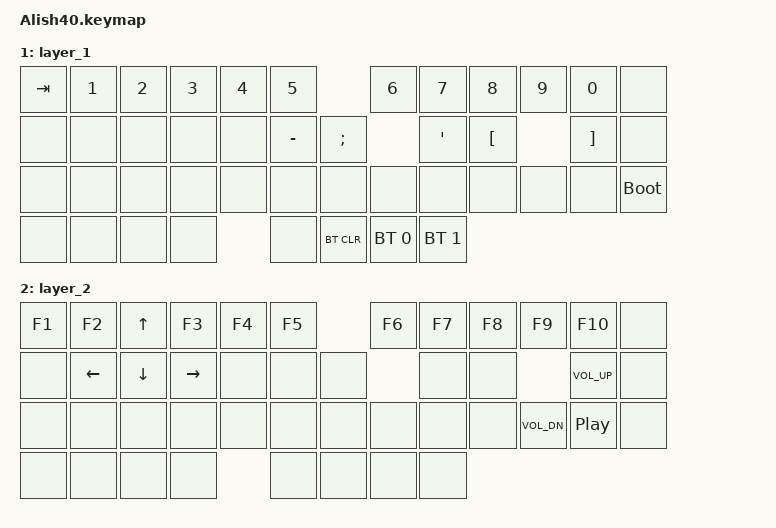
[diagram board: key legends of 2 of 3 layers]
#include <behaviors.dtsi>
#include <dt-bindings/zmk/keys.h>
#include <dt-bindings/zmk/bt.h>

/ {
    keymap {
        compatible = "zmk,keymap";

        default_layer {
            bindings = <
                &kp ESC   &kp Q   &kp W    &kp E   &kp R   &kp T   &kp Y   &kp U   &kp I   &kp O   &kp P   &kp BACKSPACE
                &kp CAPS   &kp A   &kp S    &kp D   &kp F   &kp G   &kp H   &kp J   &kp K   &kp L   &kp SQT   &kp RETURN
                &kp LSHIFT   &kp SLASH   &kp Z   &kp X   &kp C   &kp V   &kp B   &kp B   &kp N   &kp M   &kp COMMA   &kp PERIOD   &kp RSHFT
                &kp LCTRL   &kp LWIN   &mo 1   &kp SPACE   &kp SPACE   &kp RALT   &kp RWIN   &mo 2
            >;
        };

        layer_1 {
            bindings = <
                &kp TAB   &kp N1   &kp N2   &kp N3   &kp N4   &kp N5   &kp N6   &kp N7   &kp N8   &kp N9   &kp N0   &none   
                &none   &none   &none   &none   &none   &kp MINUS   &kp SEMI   &kp APOS   &kp LBKT   &kp RBKT    &none   
                &none   &none   &none   &none   &none   &none   &none   &none   &none   &none   &none   &none   &bootloader   
                &none   &none   &none   &none   &none   &bt BT_CLR   &bt BT_SEL 0   &bt BT_SEL 1   
            >;
        };

        layer_2 {
            bindings = <
                &kp F1   &kp F2   &kp UP_ARROW   &kp F3   &kp F4   &kp F5   &kp F6   &kp F7   &kp F8   &kp F9   &kp F10   &none   
                &none   &kp LEFT_ARROW   &kp DOWN_ARROW   &kp RIGHT_ARROW   &none   &none   &none   &none   &none   &kp C_VOL_UP   &none 
                &none   &none   &none   &none   &none   &none   &none   &none   &none   &none   &kp C_VOL_DN   &kp C_PP   &none 
                &none   &none   &none   &none   &none   &none   &none   &none   
            >;
        };
    };
};
